# RL6955_IP_SVD register map
Vendor: Realtek
IP svd file
Registers are 32-bit, read-write, reset 0x0 unless marked. A register's access mark holds for its fields unless they carry their own. Offsets are from the block's base; lines under a group give offsets from that group; [hi:lo] are bit positions; {n}, {i} and the like mark numbered series; 'fields as' and 'values as' point back to an identical list; <NAME> marks a mode.

## Memory map
0x40000000 WLON size 0xA8
0x40000000 MGEN_ON size 0x200
0x40000000 MGEN_OFF size 0x116C
0x40000000 WDMA size 0x218
0x40000000 AHB_LOCAL size 0x308
0x40000000 PAGE4 size 0x500
0x40000000 PAGE5_ON size 0x1508
0x40000000 PAGE5_OFF size 0x15AC
0x40000000 WMAC_PAGE6 size 0x700
0x40000000 WMAC_PAGE7 size 0x7F0
0x40000000 WMAC_PAGE17 size 0x1800
0x40080000 PKE_REG size 0x3C
0x400C0000 AES_REG size 0x1000
0x400C1000 SHA_REG size 0x1000
0x400C2000 AES_SHA_DMA_REG size 0x400
0x400C3000 AES_KEY_REG size 0x90
0x400C4000 SHA_KEY_REG size 0x50
0x400C6000 RXI300_REG_P1 size 0x1220
0x400C8000 TRNG_REG size 0x21C
0x40800000 OTPC_REG size 0x744
0x40801400 XTAL_REG size 0x50
0x40801480 WLAFE_REG size 0x70
0x40801D00 WDG0_REG size 0x14
0x40802000 UART3_REG size 0x68
0x40803000 IPC0_REG size 0x8C
0x40804000 DEBUGTIMER_REG size 0x1C
0x40805000 PMC0_TIMER_REG size 0x34
0x40806000 TIMER4_REG size 0x28
0x40806200 TIMER5_REG size 0x28
0x41000000 LP_AON size 0x100
0x41000000 SYSTEM_TZ_CTRL_BASE size 0x100
0x41000100 LDO_REG size 0x80
0x41000180 SWR_REG size 0x80
0x41000200 LP_SYS_1 size 0x100
0x41000300 PMC size 0x94
0x41000500 PLL_REG size 0x74
0x41000600 SYSTEM_MEM_CTRL size 0x1FC
0x41000800 PINMUX_REG size 0x200
0x41000A00 RTC_REG size 0x2C
0x41000C00 IWDG_REG size 0x14
0x41000D80 WDG2_REG size 0x14
0x41001000 SDM_REG size 0x24
0x41002000 UART0_REG size 0x68
0x41003000 UART1_REG size 0x68
0x41004000 UART2_REG size 0x68
0x41005000 UARTLOG_REG size 0xF4
0x41006000 IPC1_REG size 0x8C
0x41007000 PMC1_TIMER_REG size 0x34
0x41008000 TIMER0_REG size 0x28
0x41008200 TIMER1_REG size 0x28
0x41008400 TIMER2_REG size 0x28
0x41008600 TIMER3_REG size 0x28
0x41009000 GPIO_REG size 0x100
0x4100A000 ADC_REG size 0xC0
0x4100A800 CMP_REG size 0x84
0x4100B000 CTC_REG size 0x338
0x41800000 RMII_REG size 0x1440
0x41802000 GDMA0_REG size 0x400
0x41803000 CAN0_REG size 0x400
0x41804000 CAN1_REG size 0x400
0x41805000 DVP_REG size 0x84
0x41871000 UVC_REG size 0x180
0x41881000 SDIO_WIFI_REG size 0xE4
0x41882000 SDIO_BT_REG size 0xDC
0x41884000 SPORT_REG size 0x984
0x41885000 SPI0_REG size 0xB0C
0x41886000 SPI1_REG size 0xB0C
0x41888000 LCDC_REG size 0x100
0x41890000 I3C_REG size 0x2C0
0x41892000 RXI300_REG size 0x1388
0x41892100 RXI300_S_ELR_REG size 0x1388
0x41892200 RXI300_S_DIR_REG size 0x1388
0x41893000 RXI300_NS_GPR_REG size 0x1388
0x41893100 RXI300_NS_ELR_REG size 0x1388
0x41893200 RXI300_NS_DIR_REG size 0x1388
0x41893300 RXI300_NS_TMO_REG size 0x1388
0x41894000 RSIP_REG size 0x300
0x41895000 TIMER6_REG size 0x30
0x41895200 TIMER7_REG size 0x30
0x41895400 TIMER8_REG size 0x30
0x41895600 TIMER9_REG size 0x30
0x41895800 TIMER10_REG size 0x30
0x41895A00 UPS_REG size 0x30
0x41896000 I2C0_REG size 0x104
0x41897000 I2C1_REG size 0x104
0x418C0000 MJPEG_REG size 0xD4
0x41900000 PPE_REG size 0x1D0
0x41908000 PSRAM_PHY_REG size 0xFC
0x41909000 PSRAM_REG size 0x400
0x4190B000 SPI_FLASH_CTRL size 0x400
0x51000D40 WDG1_REG_S size 0x14
0x51892000 PPC_S size 0x1388
0x51892400 MPC1_S size 0x1388
0x51892500 MPC2_S size 0x1388
0x51892600 MPC3_S size 0x1388

## IPC0_REG
Base 0x40803000
Same registers: IPC1_REG 0x41006000
{0x0+4i} IPC_TX_DATA_CH{i} (i=0..15)
  [31:0] tx0_ch{i}_data — After preparing descriptor, data and corresponding memory, 1: Writing 1 to the Tx data register (tx0_data) channel x bit, and the data will be mapped to the CPU0's RX data register (rx0_data) channel x bit. And the corresponding Rx full status bit in REG_ISR_CPU0 will be set. 0: Writing 0 has no effect. If the corresponding Rx full status bit in REG_ISR_CPU0 (eg.isr_rx0_full_status6) is cleared, the corresponding bit in tx0_data will be cleaned automatically.
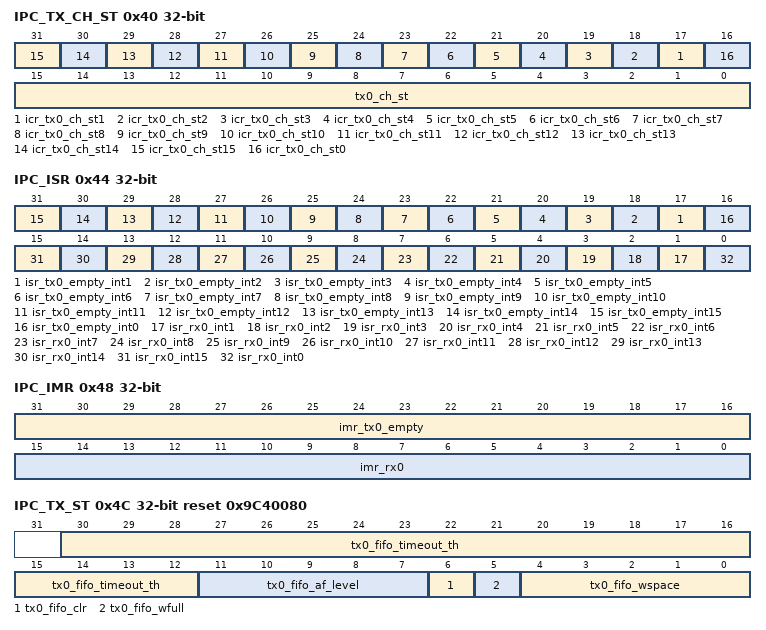
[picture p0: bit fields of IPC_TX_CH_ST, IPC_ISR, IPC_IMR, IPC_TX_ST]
0x40 IPC_TX_CH_ST access per field
  [n+16] icr_tx0_ch_st{n} ro (n=1..15) — Refer to the description of the icr_tx0_ch_st0.
  [16] icr_tx0_ch_st0 ro — 0: Writing 0 has no effect. 1: Clear the Tx data register (tx0_data) channel 0 bit.
  [15:0] tx0_ch_st rw — When sw write all ch0 data, sw will pull 1. When cpu1 receives all ch0 data,it will be automatically cleared. 0: ch0 can write 1: busy
0x44 IPC_ISR ro
  [n+16] isr_tx0_empty_int{n} (n=1..15) — Refer to the description of the isr_tx0_empty_int0
  [16] isr_tx0_empty_int0 — When all the data in ch0 is read by cpu1,it will be set to 1
  [n] isr_rx0_int{n} (n=1..15) — Refer to the description of the isr_rx0_int0
  [0] isr_rx0_int0 — fifo next pop chn0 data.when all the data in ch0 is read,it will be cleard
0x48 IPC_IMR
  [31:16] imr_tx0_empty — 0: Mask 1: Unmask
  [15:0] imr_rx0 — just useful when ipc_work_mode is 1. 0: Mask 1: Unmask
0x4C IPC_TX_ST access per field reset 0x9C40080
  [30:12] tx0_fifo_timeout_th rw — If the number of data in the FIFO is below the threshold for a period longer than that set by this register, an interrupt will be triggered.
  [11:7] tx0_fifo_af_level rw — User define the full level for afifo. the vaule must >=1.
  [6] tx0_fifo_clr wo — clear the FIFO data
  [5] tx0_fifo_wfull ro — fifo full state
  [4:0] tx0_fifo_wspace ro — the remaining writable space for the current fifo
0x50 IPC_RX_ST ro reset 0x1
  [0] rx0_fifo_empty — When fifo is empty, rx0 _ch,rx0_data is invalid
0x54 IPC_RX_DATA ro
  [31:0] rx0_data — Data info about fifo next pop data 0: fifo next pop chn0 data 1: fifo next pop chn1 data ......
0x58 IPC_SW
0x5C IPC_MODE
  [0] ipc_work_mode — 0: without share mem 1: with share mem
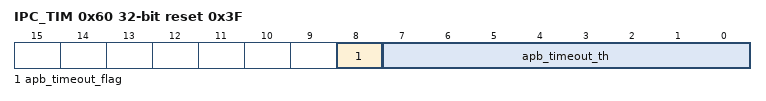
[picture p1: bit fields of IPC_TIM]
0x60 IPC_TIM access per field reset 0x3F
  [8] apb_timeout_flag ro — If apb_rdy does not reply within a certain period of time, it will be pulled.
  [7:0] apb_timeout_th rw — If apb_rdy does not reply within a certain period of time, it will automatically reply.
0x70 IPC_SEM_0 ro
  [31:0] sem_0_data — It is used to indicate who owns this semaphore .
0x74 IPC_SEM_1 ro
  [31:0] sem_1_data — It is used to indicate who owns this semaphore .
{0x78+4i} IPC_SEM_CPUID{i} ro (i=0..3)
  [31:0] sem_CPUID{i}_data — It is used to indicate who owns this semaphore .
0x88 IPC_DUMMY
  [15:0] dummy — Dummy reg

## Notices in the file
Copyright (C) 2012-2025 Realsil Limited. All rights reserved.
